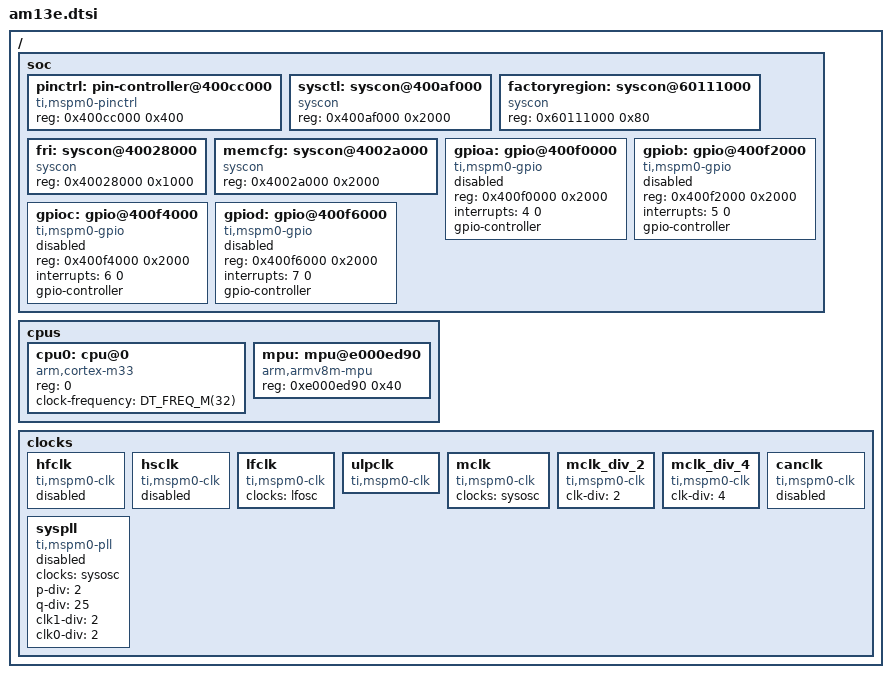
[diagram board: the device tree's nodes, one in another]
/*
 * Copyright (c) 2026 Texas Instruments Incorporated
 *
 * SPDX-License-Identifier: Apache-2.0
 */

#include <arm/armv8-m.dtsi>
#include <mem.h>
#include <freq.h>

/ {
	soc {
		pinctrl: pin-controller@400cc000 {
			compatible = "ti,mspm0-pinctrl";
			reg = <0x400cc000 0x400>;
		};
	};

	cpus {
		#address-cells = <1>;
		#size-cells = <0>;

		cpu0: cpu@0 {
			device_type = "cpu";
			compatible = "arm,cortex-m33";
			reg = <0>;
			#address-cells = <1>;
			#size-cells = <1>;
			clock-frequency = <DT_FREQ_M(32)>;
		};

		mpu: mpu@e000ed90 {
			compatible = "arm,armv8m-mpu";
			reg = <0xe000ed90 0x40>;
		};
	};

	clocks: clocks {
		hfclk: hfclk {
			#clock-cells = <0>;
			compatible = "ti,mspm0-clk";
			status = "disabled";
		};

		hsclk: hsclk {
			#clock-cells = <0>;
			compatible = "ti,mspm0-clk";
			status = "disabled";
		};

		lfclk: lfclk {
			#clock-cells = <0>;
			compatible = "ti,mspm0-clk";
			clocks = <&lfosc>;
		};

		ulpclk: ulpclk {
			#clock-cells = <0>;
			compatible = "ti,mspm0-clk";
		};

		mclk: mclk {
			#clock-cells = <0>;
			compatible = "ti,mspm0-clk";
			clocks = <&sysosc>;
		};

		mclk_div_2: mclk_div_2 {
			#clock-cells = <0>;
			compatible = "ti,mspm0-clk";
			clk-div = <2>;
		};

		mclk_div_4: mclk_div_4 {
			#clock-cells = <0>;
			compatible = "ti,mspm0-clk";
			clk-div = <4>;
		};

		canclk: canclk {
			#clock-cells = <0>;
			compatible = "ti,mspm0-clk";
			status = "disabled";
		};

		syspll: syspll {
			compatible = "ti,mspm0-pll";
			clocks = <&sysosc>;
			p-div = <2>;
			q-div = <25>;
			clk1-div = <2>;
			clk0-div = <2>;
			#clock-cells = <0>;
			status = "disabled";
		};
	};

	soc {
		sysctl: syscon@400af000 {
			compatible = "syscon";
			reg = <0x400af000 0x2000>;
			status = "okay";
		};

		factoryregion: syscon@60111000 {
			compatible = "syscon";
			reg = <0x60111000 0x80>;
		};

		fri: syscon@40028000 {
			compatible = "syscon";
			reg = <0x40028000 0x1000>;
		};

		memcfg: syscon@4002a000 {
			compatible = "syscon";
			reg = <0x4002a000 0x2000>;
		};

		/*
		 * GPIO base addresses from AM13E23019 datasheet:
		 *   GPIO0 = 0x400F_0000, GPIO1 = 0x400F_2000
		 *   GPIO2 = 0x400F_4000, GPIO3 = 0x400F_6000
		 * Interrupts TBD from AM13E NVIC table.
		 */
		/* AM13E23019 datasheet NVIC table: GPIO0=4, GPIO1=5, GPIO2=6, GPIO3=7 */
		gpioa: gpio@400f0000 {
			compatible = "ti,mspm0-gpio";
			reg = <0x400f0000 0x2000>;
			interrupts = <4 0>;
			status = "disabled";
			gpio-controller;
			#gpio-cells = <2>;
		};

		gpiob: gpio@400f2000 {
			compatible = "ti,mspm0-gpio";
			reg = <0x400f2000 0x2000>;
			interrupts = <5 0>;
			status = "disabled";
			gpio-controller;
			#gpio-cells = <2>;
		};

		gpioc: gpio@400f4000 {
			compatible = "ti,mspm0-gpio";
			reg = <0x400f4000 0x2000>;
			interrupts = <6 0>;
			status = "disabled";
			gpio-controller;
			#gpio-cells = <2>;
		};

		gpiod: gpio@400f6000 {
			compatible = "ti,mspm0-gpio";
			reg = <0x400f6000 0x2000>;
			interrupts = <7 0>;
			status = "disabled";
			gpio-controller;
			#gpio-cells = <2>;
		};
	};
};
